VERSION ""

NS_ :

BS_:

BU_: XXX

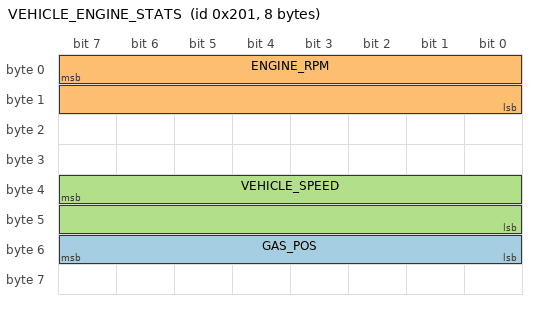
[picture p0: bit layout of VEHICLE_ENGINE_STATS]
BO_ 513 VEHICLE_ENGINE_STATS: 8 XXX
 SG_ GAS_POS : 55|8@0+ (0.5,0) [0|255] "%" XXX
 SG_ ENGINE_RPM : 7|16@0+ (1,0) [0|65535] "RPM" XXX
 SG_ VEHICLE_SPEED : 39|16@0+ (0.0062,0) [0|65535] "MPH" XXX
